AUTOSAR XML (schema 314)
package /ComponentType
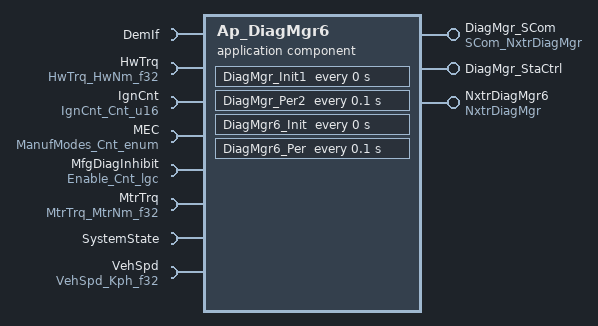
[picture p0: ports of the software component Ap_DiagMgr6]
  application software component type Ap_DiagMgr6
    provide port DiagMgr_SCom: provided-interface=SCom_NxtrDiagMgr
      provided-com-specs:
        operation=ClearBlackBox, queue-length=1
        operation=ClearLatchCounters, queue-length=1
        operation=GetNTCInfo, queue-length=1
        operation=ReadStrgArray, queue-length=1
        operation=ResetNTCStatus, queue-length=1
    provide port DiagMgr_StaCtrl: server-com-spec{operation=Shutdown, queue-length=1}, provided-interface=DiagMgr_StaCtrl
    provide port NxtrDiagMgr6: provided-interface=NxtrDiagMgr
      provided-com-specs:
        operation=GetNTCActive, queue-length=1
        operation=GetNTCFailed, queue-length=1
        operation=GetNTCStatus, queue-length=1
        operation=SetNTCStatus, queue-length=1
    8 x require port:
      DemIf: required-com-specs=[DemShutdown, RestartDem, SetEventStatus, SetOperationCycleState], required-interface=DemIf
      HwTrq: unqueued-receiver-com-spec{data-element=HwNm_f32, init-value=D_ZERO_ULS_F32}, required-interface=HwTrq_HwNm_f32
      IgnCnt: unqueued-receiver-com-spec{data-element=Cnt_u16, init-value=D_ZERO_CNT_U16}, required-interface=IgnCnt_Cnt_u16
      MEC: unqueued-receiver-com-spec{data-element=Cnt_enum, init-value=D_MANUFMODEINIT_CNT_ENUM}, required-interface=ManufModes_Cnt_enum
      MfgDiagInhibit: unqueued-receiver-com-spec{data-element=Cnt_lgc, init-value=D_FALSE_CNT_LGC}, required-interface=Enable_Cnt_lgc
      MtrTrq: unqueued-receiver-com-spec{data-element=MtrNm_f32, init-value=D_ZERO_ULS_F32}, required-interface=MtrTrq_MtrNm_f32
      SystemState: required-interface=SystemState
      VehSpd: unqueued-receiver-com-spec{data-element=Kph_f32, init-value=D_ZERO_ULS_F32}, required-interface=VehSpd_Kph_f32
  internal behavior Ap_DiagMgr6_InternalBehavior: component=Ap_DiagMgr6
    timing event DiagMgr_Init1_InitEvent: start-on-event=DiagMgr_Init1, period=0
    timing event TMT_DiagMgr_Per2: mode-dependency=dependent-on-mode=SystemState.Mode.OFF, start-on-event=DiagMgr_Per2, period=0.1
    6 x operation invoked event:
      OIT_DiagMgr_SCom_ClearBlackBox_DiagMgr_SCom_ClearBlackBox: start-on-event=DiagMgr_SCom_ClearBlackBox, operation=DiagMgr_SCom.ClearBlackBox
      OIT_DiagMgr_SCom_ClearLatchCounters_DiagMgr_SCom_ClearLatchCounters: start-on-event=DiagMgr_SCom_ClearLatchCounters, operation=DiagMgr_SCom.ClearLatchCounters
      OIT_DiagMgr_SCom_GetNTCInfo_DiagMgr_SCom_GetNTCInfo: start-on-event=DiagMgr_SCom_GetNTCInfo, operation=DiagMgr_SCom.GetNTCInfo
      OIT_DiagMgr_SCom_ReadStrgArray_DiagMgr_SCom_ReadStrgArray: start-on-event=DiagMgr_SCom_ReadStrgArray, operation=DiagMgr_SCom.ReadStrgArray
      OIT_DiagMgr_SCom_ResetNTCStatus_DiagMgr_SCom_ResetNTCStatus: start-on-event=DiagMgr_SCom_ResetNTCStatus, operation=DiagMgr_SCom.ResetNTCStatus
      OIT_DiagMgr_StaCtrl_Shutdown_DiagMgr_StaCtrl_Shutdown: start-on-event=DiagMgr_StaCtrl_Shutdown, operation=DiagMgr_StaCtrl.Shutdown
    mode switch event MST_DiagMgr_Trns1_0: start-on-event=DiagMgr_Trns1, activation=EXIT, mode=SystemState.Mode.OFF
    timing event DiagMgr6_InitEvent: start-on-event=DiagMgr6_Init, period=0
    timing event TMT_DiagMgr6_Per: start-on-event=DiagMgr6_Per, period=0.1
    mode switch event MST_DiagMgr6_Trns_0: start-on-event=DiagMgr6_Trns, activation=EXIT, mode=SystemState.Mode.OFF
    4 x operation invoked event:
      OIT_NxtrDiagMgr6_GetNTCActive_NxtrDiagMgr6_GetNTCActive: start-on-event=NxtrDiagMgr6_GetNTCActive, operation=NxtrDiagMgr6.GetNTCActive
      OIT_NxtrDiagMgr6_GetNTCFailed_NxtrDiagMgr6_GetNTCFailed: start-on-event=NxtrDiagMgr6_GetNTCFailed, operation=NxtrDiagMgr6.GetNTCFailed
      OIT_NxtrDiagMgr6_GetNTCStatus_NxtrDiagMgr6_GetNTCStatus: start-on-event=NxtrDiagMgr6_GetNTCStatus, operation=NxtrDiagMgr6.GetNTCStatus
      OIT_NxtrDiagMgr6_SetNTCStatus_NxtrDiagMgr6_SetNTCStatus: start-on-event=NxtrDiagMgr6_SetNTCStatus, operation=NxtrDiagMgr6.SetNTCStatus
    port-api-options:
      enable-take-address=false, indirect-api=false, port=DemIf
      enable-take-address=false, indirect-api=false, port=DiagMgr_SCom
      enable-take-address=false, indirect-api=false, port=DiagMgr_StaCtrl
      enable-take-address=false, indirect-api=false, port=HwTrq
      enable-take-address=false, indirect-api=false, port=IgnCnt
      enable-take-address=false, indirect-api=false, port=MEC
      enable-take-address=false, indirect-api=false, port=MfgDiagInhibit
      enable-take-address=false, indirect-api=false, port=MtrTrq
      enable-take-address=false, indirect-api=false, port=NxtrDiagMgr6
      enable-take-address=false, indirect-api=false, port=SystemState
      enable-take-address=false, indirect-api=false, port=VehSpd
    16 x runnable:
      DiagMgr_Init1
      DiagMgr_Per2
        sync call SC_DemIf_SetEventStatus: operation=DemIf.SetEventStatus, timeout=0
      DiagMgr_SCom_ClearBlackBox
      DiagMgr_SCom_ClearLatchCounters
      DiagMgr_SCom_GetNTCInfo
      DiagMgr_SCom_ReadStrgArray
      DiagMgr_SCom_ResetNTCStatus
      DiagMgr_StaCtrl_Shutdown
        sync call SC_DemIf_DemShutdown: operation=DemIf.DemShutdown, timeout=0
      DiagMgr_Trns1
        sync call SC_DemIf_RestartDem: operation=DemIf.RestartDem, timeout=0
        sync call SC_DemIf_SetOperationCycleState: operation=DemIf.SetOperationCycleState, timeout=0
      DiagMgr6_Init
        sync call SC_DemIf_SetOperationCycleState: operation=DemIf.SetOperationCycleState, timeout=0
      DiagMgr6_Per
      DiagMgr6_Trns
      NxtrDiagMgr6_GetNTCActive: can-be-invoked-concurrently=true
      NxtrDiagMgr6_GetNTCFailed: can-be-invoked-concurrently=true
      NxtrDiagMgr6_GetNTCStatus: can-be-invoked-concurrently=true
      NxtrDiagMgr6_SetNTCStatus: can-be-invoked-concurrently=true
        6 x data receive point:
          REC_HwTrq_HwNm_f32: data-element=HwTrq.HwNm_f32
          REC_IgnCnt_Cnt_u16: data-element=IgnCnt.Cnt_u16
          REC_MEC_Cnt_enum: data-element=MEC.Cnt_enum
          REC_MfgDiagInhibit_Cnt_lgc: data-element=MfgDiagInhibit.Cnt_lgc
          REC_MtrTrq_MtrNm_f32: data-element=MtrTrq.MtrNm_f32
          REC_VehSpd_Kph_f32: data-element=VehSpd.Kph_f32
  swc implementation Ap_DiagMgr6_Implementation: behavior=Ap_DiagMgr6_InternalBehavior
    code-descriptors:
      code Code: type=SRC
